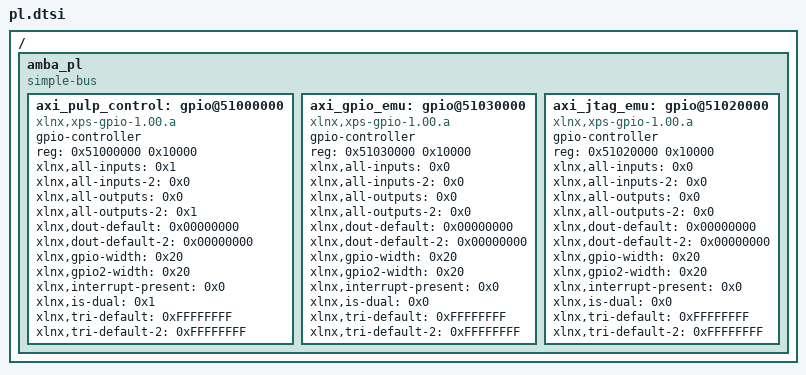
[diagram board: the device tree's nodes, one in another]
/*
 * CAUTION: This file is automatically generated by Xilinx.
 * Version:  
 * Today is: Wed Sep 16 09:21:10 2015
*/


/ {
	amba_pl: amba_pl {
		#address-cells = <1>;
		#size-cells = <1>;
		compatible = "simple-bus";
		ranges ;
		axi_pulp_control: gpio@51000000 {
			#gpio-cells = <2>;
			compatible = "xlnx,xps-gpio-1.00.a";
			gpio-controller ;
			reg = <0x51000000 0x10000>;
			xlnx,all-inputs = <0x1>;
			xlnx,all-inputs-2 = <0x0>;
			xlnx,all-outputs = <0x0>;
			xlnx,all-outputs-2 = <0x1>;
			xlnx,dout-default = <0x00000000>;
			xlnx,dout-default-2 = <0x00000000>;
			xlnx,gpio-width = <0x20>;
			xlnx,gpio2-width = <0x20>;
			xlnx,interrupt-present = <0x0>;
			xlnx,is-dual = <0x1>;
			xlnx,tri-default = <0xFFFFFFFF>;
			xlnx,tri-default-2 = <0xFFFFFFFF>;
		};
		axi_gpio_emu: gpio@51030000 {
			#gpio-cells = <2>;
			compatible = "xlnx,xps-gpio-1.00.a";
			gpio-controller ;
			reg = <0x51030000 0x10000>;
			xlnx,all-inputs = <0x0>;
			xlnx,all-inputs-2 = <0x0>;
			xlnx,all-outputs = <0x0>;
			xlnx,all-outputs-2 = <0x0>;
			xlnx,dout-default = <0x00000000>;
			xlnx,dout-default-2 = <0x00000000>;
			xlnx,gpio-width = <0x20>;
			xlnx,gpio2-width = <0x20>;
			xlnx,interrupt-present = <0x0>;
			xlnx,is-dual = <0x0>;
			xlnx,tri-default = <0xFFFFFFFF>;
			xlnx,tri-default-2 = <0xFFFFFFFF>;
		};
		axi_jtag_emu: gpio@51020000 {
			#gpio-cells = <2>;
			compatible = "xlnx,xps-gpio-1.00.a";
			gpio-controller ;
			reg = <0x51020000 0x10000>;
			xlnx,all-inputs = <0x0>;
			xlnx,all-inputs-2 = <0x0>;
			xlnx,all-outputs = <0x0>;
			xlnx,all-outputs-2 = <0x0>;
			xlnx,dout-default = <0x00000000>;
			xlnx,dout-default-2 = <0x00000000>;
			xlnx,gpio-width = <0x20>;
			xlnx,gpio2-width = <0x20>;
			xlnx,interrupt-present = <0x0>;
			xlnx,is-dual = <0x0>;
			xlnx,tri-default = <0xFFFFFFFF>;
			xlnx,tri-default-2 = <0xFFFFFFFF>;
		};
	};
};
